AUTOSAR XML (schema 4-0-3)
package /ComponentTypes
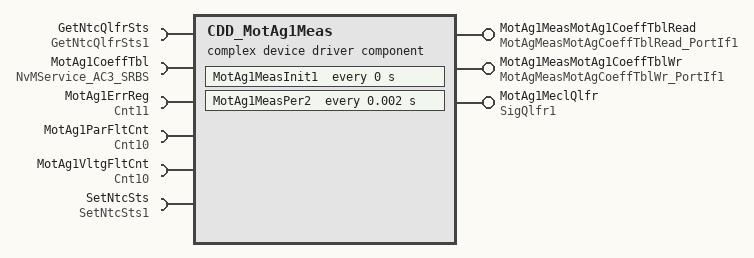
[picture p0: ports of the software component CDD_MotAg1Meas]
  complex device driver sw component type CDD_MotAg1Meas
    provide port MotAg1MeasMotAg1CoeffTblRead: server-com-spec{operation=Oper, queue-length=1}, provided-interface=MotAgMeasMotAgCoeffTblRead_PortIf1
    provide port MotAg1MeasMotAg1CoeffTblWr: server-com-spec{operation=Oper, queue-length=1}, provided-interface=MotAgMeasMotAgCoeffTblWr_PortIf1
    provide port MotAg1MeclQlfr: nonqueued-sender-com-spec{data-element=Val, init-value=0}, provided-interface=SigQlfr1
    6 x require port:
      GetNtcQlfrSts: required-interface=GetNtcQlfrSts1
      MotAg1CoeffTbl: required-interface=NvMService_AC3_SRBS
      MotAg1ErrReg: nonqueued-receiver-com-spec{data-element=Val, filter=data-filter-type=ALWAYS, init-value=0}, required-interface=Cnt11
      MotAg1ParFltCnt: nonqueued-receiver-com-spec{data-element=Val, filter=data-filter-type=ALWAYS, init-value=0}, required-interface=Cnt10
      MotAg1VltgFltCnt: nonqueued-receiver-com-spec{data-element=Val, filter=data-filter-type=ALWAYS, init-value=0}, required-interface=Cnt10
      SetNtcSts: required-interface=SetNtcSts1
    behavior CDD_MotAg1Meas_InternalBehavior: data-type-mapping=Nexteer
      ar-typed-per-instance-memorys:
        14 x data, all with sw-calibration-access=READ-ONLY:
          dMotAg1MeasMotAg1RawAgReg: type=Cnt17
          dMotAg1MeasMotAg1RawErrReg: type=Cnt17
          dMotAg1MeasMotAg1RawTurnCntrReg: type=Cnt17
          MotAg1CoeffTbl: type=Ary1D_f32_26
          MotAg1CorrnTbl: type=Ary1D_sm5p12_128
          MotAg1ErrParFltCntPrev: type=Cnt16
          MotAg1ErrParFltNtcStInfoCntPrev: type=Cnt16
          MotAg1ErrPrev: type=Cnt18
          MotAg1MeclRollgCntrPrev: type=Cnt19
          MotAg1ParFltCntPrev: type=Cnt16
          MotAg1ParFltNtcStInfoCntPrev: type=Cnt16
          MotAg1RawMeclPrev: type=Ag5
          MotAg1VltgFltCntPrev: type=Cnt16
          MotAg1VltgFltNtcStInfoCntPrev: type=Cnt16
      timing event CDD_MotAg1Meas_InitEvent: start-on-event=MotAg1MeasInit1, period=0
      operation invoked event OIT_MotAg1MeasMotAg1CoeffTblRead_Oper_MotAg1MeasMotAg1CoeffTblRead_Oper: start-on-event=MotAg1MeasMotAg1CoeffTblRead_Oper, operation=MotAg1MeasMotAg1CoeffTblRead.Oper
      operation invoked event OIT_MotAg1MeasMotAg1CoeffTblWr_Oper_MotAg1MeasMotAg1CoeffTblWr_Oper: start-on-event=MotAg1MeasMotAg1CoeffTblWr_Oper, operation=MotAg1MeasMotAg1CoeffTblWr.Oper
      timing event TMT_MotAg1MeasPer2: start-on-event=MotAg1MeasPer2, period=0.002
      4 x runnable:
        MotAg1MeasInit1
          sync call SC_MotAg1CoeffTbl_GetErrorStatus_1: operation=MotAg1CoeffTbl.GetErrorStatus, timeout=0
        MotAg1MeasMotAg1CoeffTblRead_Oper
        MotAg1MeasMotAg1CoeffTblWr_Oper
          sync call SC_MotAg1CoeffTbl_SetRamBlockStatus_1: operation=MotAg1CoeffTbl.SetRamBlockStatus, timeout=0
        MotAg1MeasPer2
          data-receive-point-by-arguments:
            access REC_MotAg1ErrReg_Val: accessed-variable=MotAg1ErrReg.Val
            access REC_MotAg1ParFltCnt_Val: accessed-variable=MotAg1ParFltCnt.Val
            access REC_MotAg1VltgFltCnt_Val: accessed-variable=MotAg1VltgFltCnt.Val
          data-send-points:
            access SEND_MotAg1MeclQlfr_Val: accessed-variable=MotAg1MeclQlfr.Val
          sync call SC_GetNtcQlfrSts_Oper: operation=GetNtcQlfrSts.Oper, timeout=0
          sync call SC_SetNtcSts_Oper: operation=SetNtcSts.Oper, timeout=0
      swc service dependency NvmMotAg1CoeffTbl
        assigned-datas:
          role=ramBlock, used-data-element=MotAg1CoeffTbl
          role=defaultValue, used-parameter-element=MotAg1CoeffTblDft
        assigned-ports:
          port-prototype=MotAg1CoeffTbl, role=NvMService_AC3_SRBS
          port-prototype=MotAg1CoeffTbl, role=NvMService_AC3_SRBS
        service-needs:
          nv block needs NvmMotAg1CoeffTbl: n-data-sets=0, readonly=false, reliability=ERROR-DETECTION, resistant-to-changed-sw=true, restore-at-start=true, store-at-shutdown=true, write-only-once=false, writing-frequency=0, writing-priority=LOW
      shared-parameters:
        parameter data prototype MotAg1CoeffTblDft: sw-calibration-access=READ-WRITE, type=Ary1D_f32_26, init-value=26 x 0
  swc implementation CDD_MotAg1Meas_Implementation: behavior=CDD_MotAg1Meas_InternalBehavior
    code-descriptors:
      code Default: artifact-descriptors=autosar-engineering-object={short-label=Default, category=SWSRC}
